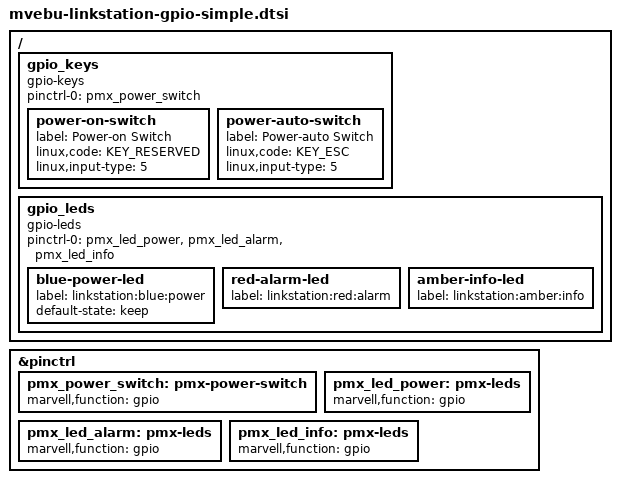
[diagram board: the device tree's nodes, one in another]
#include <dt-bindings/input/input.h>
/ {
	gpio_keys {
		compatible = "gpio-keys";
		#address-cells = <1>;
		#size-cells = <0>;
		pinctrl-0 = <&pmx_power_switch>;
		pinctrl-names = "default";
		power-on-switch {
			label = "Power-on Switch";
			linux,code = <KEY_RESERVED>;
			linux,input-type = <5>;
		};
		power-auto-switch {
			label = "Power-auto Switch";
			linux,code = <KEY_ESC>;
			linux,input-type = <5>;
		};
	};
	gpio_leds {
		compatible = "gpio-leds";
		pinctrl-0 = <&pmx_led_power &pmx_led_alarm &pmx_led_info>;
		pinctrl-names = "default";
		blue-power-led {
			label = "linkstation:blue:power";
			default-state = "keep";
		};
		red-alarm-led {
			label = "linkstation:red:alarm";
		};
		amber-info-led {
			label = "linkstation:amber:info";
		};
	};
};
&pinctrl {
	pmx_power_switch: pmx-power-switch {
		marvell,function = "gpio";
	};
	pmx_led_power: pmx-leds {
		marvell,function = "gpio";
	};
	pmx_led_alarm: pmx-leds {
		marvell,function = "gpio";
	};
	pmx_led_info: pmx-leds {
		marvell,function = "gpio";
	};
};
